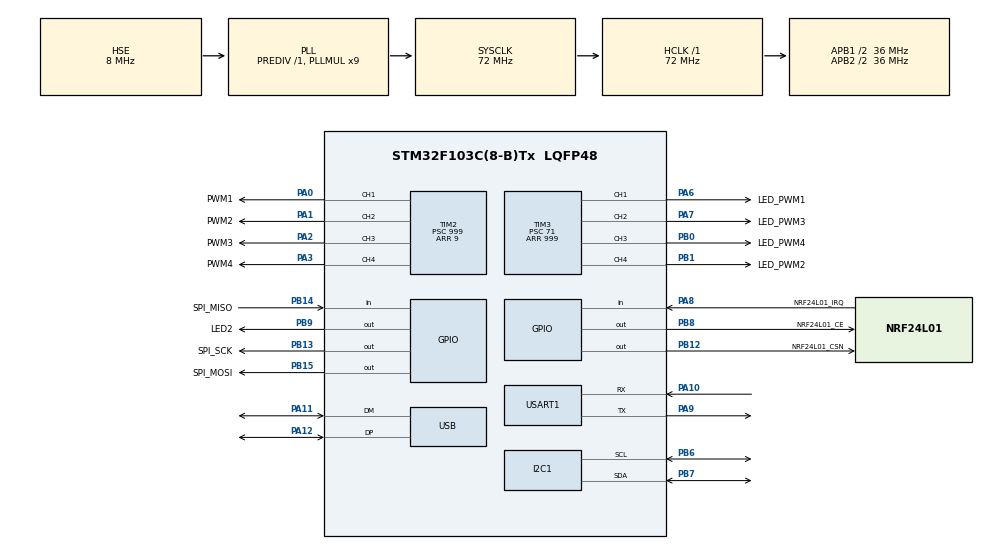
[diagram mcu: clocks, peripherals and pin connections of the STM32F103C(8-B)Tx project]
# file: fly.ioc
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Mcu.Family=STM32F1
Mcu.Name=STM32F103C(8-B)Tx
Mcu.Package=LQFP48
NVIC.PriorityGroup=NVIC_PRIORITYGROUP_4
NVIC.TIM4_IRQn=true\:0\:0\:false\:false\:true\:true\:true\:true
NVIC.USB_LP_CAN1_RX0_IRQn=true\:0\:0\:false\:false\:true\:true\:true\:true
PA0-WKUP.GPIO_Label=PWM1
PA0-WKUP.Signal=S_TIM2_CH1_ETR
PA1.GPIO_Label=PWM2
PA1.Signal=S_TIM2_CH2
PA10.Mode=Asynchronous
PA10.Signal=USART1_RX
PA11.Mode=Device
PA11.Signal=USB_DM
PA12.Mode=Device
PA12.Signal=USB_DP
PA13.Mode=Serial_Wire
PA13.Signal=SYS_JTMS-SWDIO
PA14.Mode=Serial_Wire
PA14.Signal=SYS_JTCK-SWCLK
PA2.GPIO_Label=PWM3
PA2.Signal=S_TIM2_CH3
PA3.GPIO_Label=PWM4
PA3.Signal=S_TIM2_CH4
PA6.GPIO_Label=LED_PWM1
PA6.Signal=S_TIM3_CH1
PA7.GPIO_Label=LED_PWM3
PA7.Signal=S_TIM3_CH2
PA8.GPIO_Label=NRF24L01_IRQ
PA8.GPIO_PuPd=GPIO_NOPULL
PA8.Signal=GPIO_Input
PA9.Mode=Asynchronous
PA9.Signal=USART1_TX
PB0.GPIO_Label=LED_PWM4
PB0.Signal=S_TIM3_CH3
PB1.GPIO_Label=LED_PWM2
PB1.Signal=S_TIM3_CH4
PB12.GPIO_Label=NRF24L01_CSN
PB12.GPIO_Speed=GPIO_SPEED_FREQ_HIGH
PB12.PinState=GPIO_PIN_SET
PB12.Signal=GPIO_Output
PB13.GPIO_Label=SPI_SCK
PB13.GPIO_Speed=GPIO_SPEED_FREQ_HIGH
PB13.Signal=GPIO_Output
PB14.GPIO_Label=SPI_MISO
PB14.Signal=GPIO_Input
PB15.GPIO_Label=SPI_MOSI
PB15.GPIO_Speed=GPIO_SPEED_FREQ_HIGH
PB15.PinState=GPIO_PIN_SET
PB15.Signal=GPIO_Output
PB6.Mode=I2C
PB6.Signal=I2C1_SCL
PB7.Mode=I2C
PB7.Signal=I2C1_SDA
PB8.GPIO_Label=NRF24L01_CE
PB8.GPIO_Speed=GPIO_SPEED_FREQ_HIGH
PB8.PinState=GPIO_PIN_SET
PB8.Signal=GPIO_Output
PB9.GPIO_Label=LED2
PB9.Signal=GPIO_Output
PD0-OSC_IN.Mode=HSE-External-Oscillator
PD0-OSC_IN.Signal=RCC_OSC_IN
PD1-OSC_OUT.Mode=HSE-External-Oscillator
PD1-OSC_OUT.Signal=RCC_OSC_OUT
ProjectManager.HeapSize=0x200
ProjectManager.StackSize=0x400
ProjectManager.TargetToolchain=CMake
RCC.AHBFreq_Value=72000000
RCC.APB1CLKDivider=RCC_HCLK_DIV2
RCC.APB1Freq_Value=36000000
RCC.APB1TimFreq_Value=72000000
RCC.APB2CLKDivider=RCC_HCLK_DIV2
RCC.APB2Freq_Value=36000000
RCC.APB2TimFreq_Value=72000000
RCC.HCLKFreq_Value=72000000
RCC.PLLMUL=RCC_PLL_MUL9
RCC.PLLSourceVirtual=RCC_PLLSOURCE_HSE
RCC.SYSCLKFreq_VALUE=72000000
RCC.SYSCLKSource=RCC_SYSCLKSOURCE_PLLCLK
RCC.USBFreq_Value=48000000
RCC.USBPrescaler=RCC_USBCLKSOURCE_PLL_DIV1_5
SH.S_TIM2_CH1_ETR.0=TIM2_CH1,PWM Generation1 CH1
SH.S_TIM2_CH2.0=TIM2_CH2,PWM Generation2 CH2
SH.S_TIM2_CH3.0=TIM2_CH3,PWM Generation3 CH3
SH.S_TIM2_CH4.0=TIM2_CH4,PWM Generation4 CH4
SH.S_TIM3_CH1.0=TIM3_CH1,PWM Generation1 CH1
SH.S_TIM3_CH2.0=TIM3_CH2,PWM Generation2 CH2
SH.S_TIM3_CH3.0=TIM3_CH3,PWM Generation3 CH3
SH.S_TIM3_CH4.0=TIM3_CH4,PWM Generation4 CH4
TIM2.AutoReloadPreload=TIM_AUTORELOAD_PRELOAD_ENABLE
TIM2.Channel-PWM\ Generation1\ CH1=TIM_CHANNEL_1
TIM2.Channel-PWM\ Generation2\ CH2=TIM_CHANNEL_2
TIM2.Channel-PWM\ Generation3\ CH3=TIM_CHANNEL_3
TIM2.Channel-PWM\ Generation4\ CH4=TIM_CHANNEL_4
TIM2.Period=9
TIM2.Prescaler=999
TIM2.Pulse-PWM\ Generation1\ CH1=0
TIM3.AutoReloadPreload=TIM_AUTORELOAD_PRELOAD_ENABLE
TIM3.Channel-PWM\ Generation1\ CH1=TIM_CHANNEL_1
TIM3.Channel-PWM\ Generation2\ CH2=TIM_CHANNEL_2
TIM3.Channel-PWM\ Generation3\ CH3=TIM_CHANNEL_3
TIM3.Channel-PWM\ Generation4\ CH4=TIM_CHANNEL_4
TIM3.OCPolarity_1=TIM_OCPOLARITY_HIGH
TIM3.OCPolarity_2=TIM_OCPOLARITY_HIGH
TIM3.OCPolarity_3=TIM_OCPOLARITY_HIGH
TIM3.OCPolarity_4=TIM_OCPOLARITY_HIGH
TIM3.Period=999
TIM3.Prescaler=71
TIM3.Pulse-PWM\ Generation1\ CH1=999
TIM3.Pulse-PWM\ Generation2\ CH2=999
TIM3.Pulse-PWM\ Generation3\ CH3=999
TIM3.Pulse-PWM\ Generation4\ CH4=999
TIM4.AutoReloadPreload=TIM_AUTORELOAD_PRELOAD_ENABLE
TIM4.Period=1000
TIM4.Prescaler=71
USART1.VirtualMode=VM_ASYNC
USB_DEVICE.CLASS_NAME_FS=CDC
USB_DEVICE.VirtualMode=Cdc
USB_DEVICE.VirtualModeFS=Cdc_FS
VP_TIM2_VS_ClockSourceINT.Mode=Internal
VP_TIM3_VS_ClockSourceINT.Mode=Internal
VP_TIM4_VS_ClockSourceINT.Mode=Internal
VP_USB_DEVICE_VS_USB_DEVICE_CDC_FS.Mode=CDC_FS
board=custom

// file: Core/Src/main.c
/* USER CODE BEGIN Header */
/**
 ******************************************************************************
 * @file           : main.c
 * @brief          : Main program body
 ******************************************************************************
 * @attention
 *
 * Copyright (c) 2024 STMicroelectronics.
 * All rights reserved.
 *
 * This software is licensed under terms that can be found in the LICENSE file
 * in the root directory of this software component.
 * If no LICENSE file comes with this software, it is provided AS-IS.
 *
 ******************************************************************************
 */
/* USER CODE END Header */
#include "main.h"
#include "i2c.h"
#include "tim.h"
#include "usart.h"
#include "usb_device.h"
#include "gpio.h"

/* USER CODE BEGIN Includes */
#include "led.h"
#include "mpu6050.h"
#include "nrf24l01.h"
/* USER CODE END Includes */

void SystemClock_Config(void);

int main(void)
{

  /* MCU Configuration--------------------------------------------------------*/

  /* Reset of all peripherals, Initializes the Flash interface and the Systick. */
  HAL_Init();

  /* Configure the system clock */
  SystemClock_Config();

  /* Initialize all configured peripherals */
  MX_GPIO_Init();
  MX_I2C1_Init();
  MX_TIM2_Init();
  MX_TIM4_Init();
  MX_TIM3_Init();
  MX_USART1_UART_Init();
  MX_USB_DEVICE_Init();
  /* USER CODE BEGIN 2 */
  if (MPU6050_Init() != HAL_OK) {
    jlink("MPU6050 Init Failed\n");
    Error_Handler();
  }
  jlink("MPU6050 Init Success\n");
  NRF24L01_Init();
  /* USER CODE END 2 */

  /* Infinite loop */
  /* USER CODE BEGIN WHILE */
  GW_TIM_Start();
  while (1) {
    /* USER CODE END WHILE */

    /* USER CODE BEGIN 3 */
    GW_LED_Status();
  }
  /* USER CODE END 3 */
}

void SystemClock_Config(void)
{
  RCC_OscInitTypeDef RCC_OscInitStruct = {0};
  RCC_ClkInitTypeDef RCC_ClkInitStruct = {0};
  RCC_PeriphCLKInitTypeDef PeriphClkInit = {0};

  /** Initializes the RCC Oscillators according to the specified parameters
  * in the RCC_OscInitTypeDef structure.
  */
  RCC_OscInitStruct.OscillatorType = RCC_OSCILLATORTYPE_HSE;
  RCC_OscInitStruct.HSEState = RCC_HSE_ON;
  RCC_OscInitStruct.HSEPredivValue = RCC_HSE_PREDIV_DIV1;
  RCC_OscInitStruct.HSIState = RCC_HSI_ON;
  RCC_OscInitStruct.PLL.PLLState = RCC_PLL_ON;
  RCC_OscInitStruct.PLL.PLLSource = RCC_PLLSOURCE_HSE;
  RCC_OscInitStruct.PLL.PLLMUL = RCC_PLL_MUL9;
  if (HAL_RCC_OscConfig(&RCC_OscInitStruct) != HAL_OK)
  {
    Error_Handler();
  }

  /** Initializes the CPU, AHB and APB buses clocks
  */
  RCC_ClkInitStruct.ClockType = RCC_CLOCKTYPE_HCLK|RCC_CLOCKTYPE_SYSCLK
                              |RCC_CLOCKTYPE_PCLK1|RCC_CLOCKTYPE_PCLK2;
  RCC_ClkInitStruct.SYSCLKSource = RCC_SYSCLKSOURCE_PLLCLK;
  RCC_ClkInitStruct.AHBCLKDivider = RCC_SYSCLK_DIV1;
  RCC_ClkInitStruct.APB1CLKDivider = RCC_HCLK_DIV2;
  RCC_ClkInitStruct.APB2CLKDivider = RCC_HCLK_DIV2;

  if (HAL_RCC_ClockConfig(&RCC_ClkInitStruct, FLASH_LATENCY_2) != HAL_OK)
  {
    Error_Handler();
  }
  PeriphClkInit.PeriphClockSelection = RCC_PERIPHCLK_USB;
  PeriphClkInit.UsbClockSelection = RCC_USBCLKSOURCE_PLL_DIV1_5;
  if (HAL_RCCEx_PeriphCLKConfig(&PeriphClkInit) != HAL_OK)
  {
    Error_Handler();
  }
}

void Error_Handler(void)
{
  __disable_irq();
  while (1) {
  }
}

#ifdef  USE_FULL_ASSERT
/**
  * @brief  Reports the name of the source file and the source line number
  *         where the assert_param error has occurred.
  * @param  file: pointer to the source file name
  * @param  line: assert_param error line source number
  * @retval None
  */
void assert_failed(uint8_t *file, uint32_t line)
{
  /* USER CODE BEGIN 6 */
  /* User can add his own implementation to report the file name and line
     number, ex: printf("Wrong parameters value: file %s on line %d\r\n", file,
     line) */
  /* USER CODE END 6 */
}
#endif /* USE_FULL_ASSERT */
